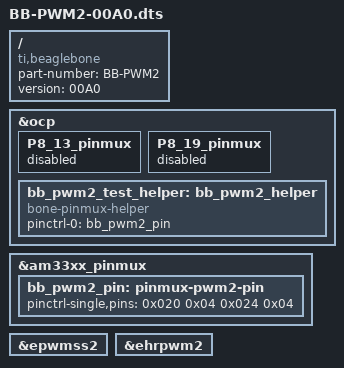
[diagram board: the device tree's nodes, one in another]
/*
 * Copyright (C) 2016 Seeed Studio.
 *
 * This program is free software; you can redistribute it and/or modify
 * it under the terms of the GNU General Public License version 2 as
 * published by the Free Software Foundation.
 */

/dts-v1/;
/plugin/;

#include <dt-bindings/gpio/gpio.h>
#include <dt-bindings/pinctrl/am33xx.h>

/{
	compatible = "ti,beaglebone", "ti,beaglebone-black", "ti,beaglebone-green";
	part-number = "BB-PWM2";
	version = "00A0";

	/*
	 * Free up the pins used by the cape from the pinmux helpers.
	 */
	fragment@0 {
		target = <&ocp>;
		__overlay__ {
			P8_13_pinmux { status = "disabled"; };	/* (T10) gpmc_ad9.ehrpwm2B */
			P8_19_pinmux { status = "disabled"; };	/* (U10) gpmc_ad8.ehrpwm2A */
		};
	};

	fragment@1 {
		target = <&am33xx_pinmux>;
		__overlay__ {
			bb_pwm2_pin: pinmux-pwm2-pin {
				pinctrl-single,pins = <
					0x020 0x04 /* P8_19 MODE4 ehrpwm2A PWM */
					0x024 0x04 /* P8_13 MODE4 EHRPWM2B PWM */
				>;
			};
		};
	};

	fragment@2 {
		target = <&ocp>;
		__overlay__ {
			bb_pwm2_test_helper: bb_pwm2_helper {
				compatible = "bone-pinmux-helper";
				pinctrl-names = "default";
				pinctrl-0 = <&bb_pwm2_pin>;
				status = "okay";
			};
		};
	};

	fragment@3 {
		target = <&epwmss2>;
		__overlay__ {
			status = "okay";
		};
	};

	fragment@4 {
		target = <&ehrpwm2>;
		__overlay__ {
			status = "okay";
		};
	};
};
